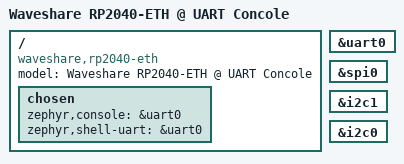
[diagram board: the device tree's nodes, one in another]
/*
 * Copyright (c) 2023 TiaC Systems
 * SPDX-License-Identifier: Apache-2.0
 */

/dts-v1/;

/ {
	model = "Waveshare RP2040-ETH @ UART Concole";
	compatible = "waveshare,rp2040-eth", "waveshare,rp2040-eth-uartcons";

	chosen {
		zephyr,console = &uart0;
		zephyr,shell-uart = &uart0;
	};
};

#include "waveshare_rp2040-mini.dtsi"
#include "waveshare_rp2040-4mb.dtsi"

#include "rpipico_led_ws2812.dtsi"
#include "rpipico_eth_ch9120.dtsi"
#include "rpipico_reduced_connector.dtsi"
#include "rpipico_reduced_r3_connector.dtsi"

rpipico_serial: &uart0 {};
rpipico_spi0: &spi0 {};
rpipico_spi: &rpipico_spi0 {};
rpipico_i2c1: &i2c1 {};
rpipico_i2c0: &i2c0 {};
rpipico_i2c: &rpipico_i2c0 {};

pico_serial: &rpipico_serial {};
pico_spi0: &rpipico_spi0 {};
pico_spi: &pico_spi0 {};
pico_i2c1: &rpipico_i2c1 {};
pico_i2c0: &rpipico_i2c0 {};
pico_i2c: &pico_i2c0 {};

#include "waveshare_rp2040-mini-tweaks.dtsi"
